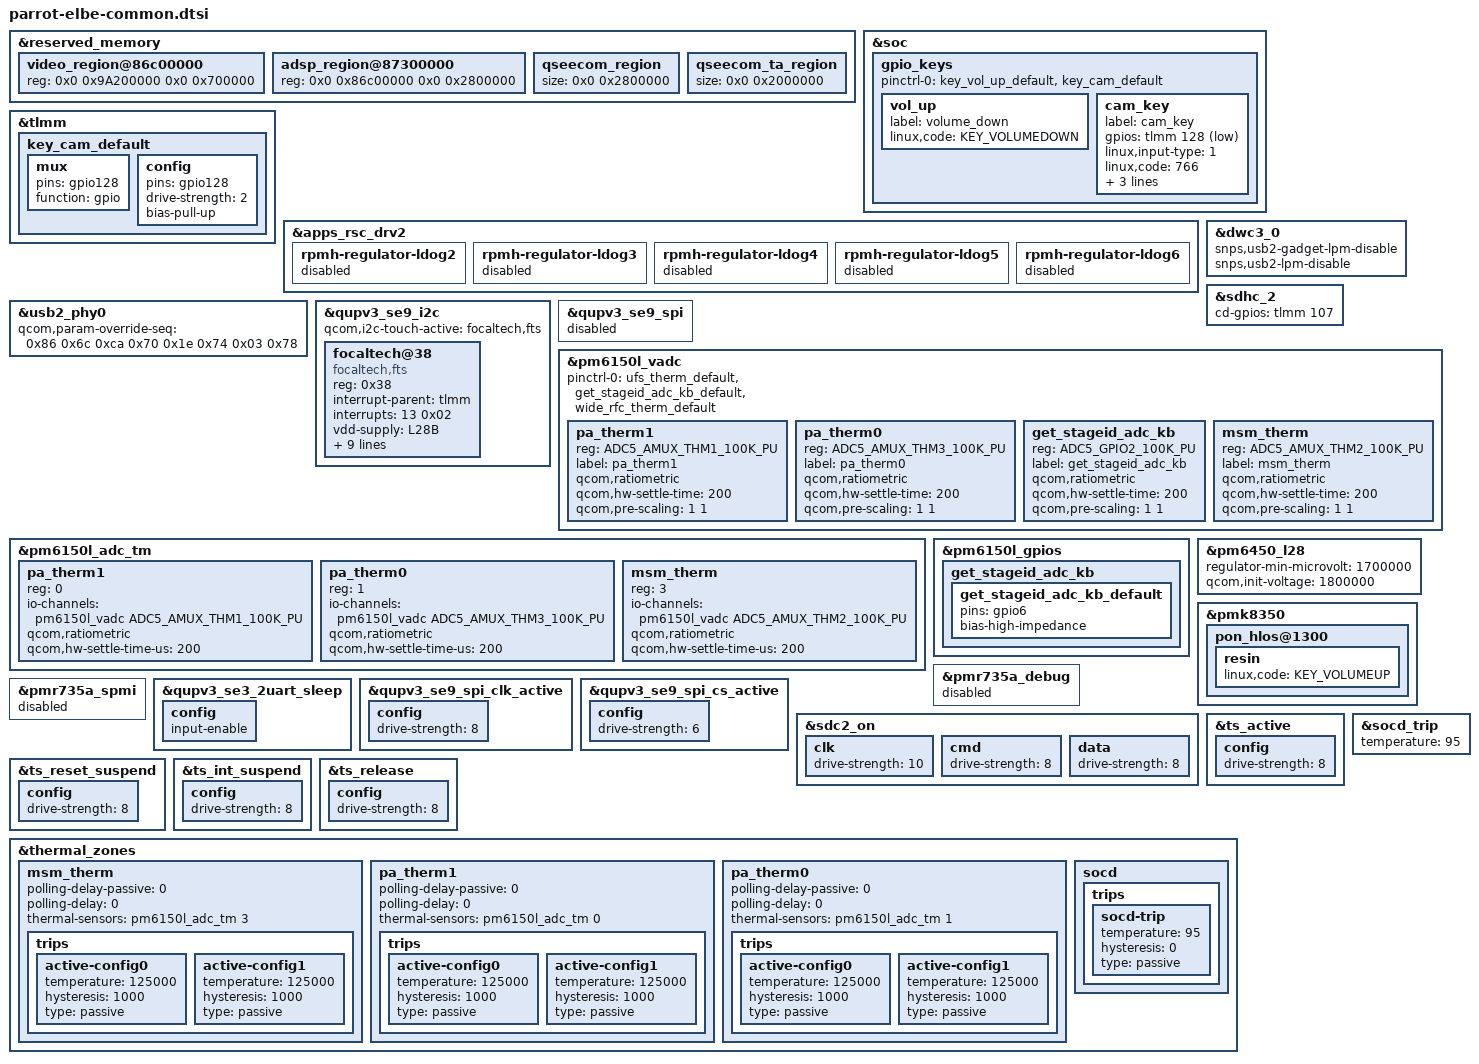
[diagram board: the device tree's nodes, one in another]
&reserved_memory {
	#address-cells = <2>;
	#size-cells = <2>;

	video_region@86c00000 {
		reg = <0x0 0x9A200000 0x0 0x700000>;
	};

	adsp_region@87300000 {
		reg = <0x0 0x86c00000 0x0 0x2800000>;
	};

	qseecom_region {
		size = <0x0 0x2800000>;
	};

	qseecom_ta_region {
		size = <0x0 0x2000000>;
	};
};

&soc {
	gpio_keys {
		pinctrl-0 = <&key_vol_up_default &key_cam_default>;

		vol_up {
			label = "volume_down";
			linux,code = <KEY_VOLUMEDOWN>;
		};

		cam_key {
			label = "cam_key";
			gpios = <&tlmm 128 GPIO_ACTIVE_LOW>;
			linux,input-type = <1>;
			linux,code = <766>;
			gpio-key,wakeup;
			debounce-interval = <15>;
			linux,can-disable;
		};
	};
};

&tlmm {
	key_cam_default: key_cam_default {
		mux {
			pins = "gpio128";
			function = "gpio";
		};

		config {
			pins = "gpio128";
			drive-strength = <2>;
			bias-pull-up;
		};
	};
};

&apps_rsc_drv2 {
	rpmh-regulator-ldog2 {
		status = "disabled";
	};

	rpmh-regulator-ldog3 {
		status = "disabled";
	};

	rpmh-regulator-ldog4 {
		status = "disabled";
	};

	rpmh-regulator-ldog5 {
		status = "disabled";
	};

	rpmh-regulator-ldog6 {
		status = "disabled";
	};
};

&dwc3_0 {
	snps,usb2-gadget-lpm-disable;
	snps,usb2-lpm-disable;
};

&usb2_phy0 {
	qcom,param-override-seq = <
		0x86 0x6c
		0xca 0x70
		0x1e 0x74
		0x03 0x78>;
};

&sdhc_2 {
	cd-gpios = <&tlmm 107 GPIO_ACTIVE_HIGH>;

	/delete-property/ no-sdio;
	/delete-property/ no-mmc;
};

&qupv3_se9_i2c {
	#address-cells = <1>;
	#size-cells = <0>;
	qcom,i2c-touch-active = "focaltech,fts";
	status = "okay";

	focaltech@38 {
		compatible = "focaltech,fts";
		reg = <0x38>;
		interrupt-parent = <&tlmm>;
		interrupts = <13 0x02>;
		vdd-supply = <&L28B>;
		focaltech,reset-gpio = <&tlmm 12 0x01>;
		focaltech,irq-gpio = <&tlmm 13 0x02>;
		focaltech,max-touch-number = <10>;
		focaltech,display-coords =  <0 0 1080 2340>;
		focaltech,avdd-gpio = <&tlmm 103 0x0>;
		pinctrl-names = "pmx_ts_active", "pmx_ts_suspend", "pmx_ts_release";
		pinctrl-0 = <&ts_active>;
		pinctrl-1 = <&ts_int_suspend &ts_reset_suspend>;
		pinctrl-2 = <&ts_release>;

		panel = <&dsi_samsung_amoled_cmd>;
	};
};

&qupv3_se9_spi {
	status = "disabled";
};

&pm6150l_vadc {
	pinctrl-0 = <&ufs_therm_default &get_stageid_adc_kb_default &wide_rfc_therm_default>;

	/delete-node/ pa_therm2;
	/delete-node/ pa_therm1;
	/delete-node/ wide_rfc_therm;

	pa_therm1 {
		reg = <ADC5_AMUX_THM1_100K_PU>;
		label = "pa_therm1";
		qcom,ratiometric;
		qcom,hw-settle-time = <200>;
		qcom,pre-scaling = <1 1>;
	};

	pa_therm0 {
		reg = <ADC5_AMUX_THM3_100K_PU>;
		label = "pa_therm0";
		qcom,ratiometric;
		qcom,hw-settle-time = <200>;
		qcom,pre-scaling = <1 1>;
	};

	get_stageid_adc_kb {
		reg = <ADC5_GPIO2_100K_PU>;
		label = "get_stageid_adc_kb";
		qcom,ratiometric;
		qcom,hw-settle-time = <200>;
		qcom,pre-scaling = <1 1>;
	};

	msm_therm {
		reg = <ADC5_AMUX_THM2_100K_PU>;
		label = "msm_therm";
		qcom,ratiometric;
		qcom,hw-settle-time = <200>;
		qcom,pre-scaling = <1 1>;
	};
};

&pm6150l_adc_tm {
	/delete-node/ pa_therm2;
	/delete-node/ pa_therm1;
	/delete-node/ wide_rfc_therm;

	pa_therm1 {
		reg = <0>;
		io-channels = <&pm6150l_vadc ADC5_AMUX_THM1_100K_PU>;
		qcom,ratiometric;
		qcom,hw-settle-time-us = <200>;
	};

	pa_therm0 {
		reg = <1>;
		io-channels = <&pm6150l_vadc ADC5_AMUX_THM3_100K_PU>;
		qcom,ratiometric;
		qcom,hw-settle-time-us = <200>;
	};

	msm_therm {
		reg = <3>;
		io-channels = <&pm6150l_vadc ADC5_AMUX_THM2_100K_PU>;
		qcom,ratiometric;
		qcom,hw-settle-time-us = <200>;
	};
};

&pm6150l_gpios {
	get_stageid_adc_kb {
		get_stageid_adc_kb_default: get_stageid_adc_kb_default {
			pins = "gpio6";
			bias-high-impedance;
		};
	};
};

&pm6450_l28 {
	regulator-min-microvolt = <1700000>;
	qcom,init-voltage = <1800000>;
};

&pmk8350 {
	pon_hlos@1300 {
		resin {
			linux,code = <KEY_VOLUMEUP>;
		};
	};
};

&pmr735a_debug {
	status = "disabled";
};

&pmr735a_spmi {
	status = "disabled";
};

&qupv3_se3_2uart_sleep {
	config {
		input-enable;
	};
};

&qupv3_se9_spi_clk_active {
	config {
		drive-strength = <8>;
	};
};

&qupv3_se9_spi_cs_active {
	config {
		drive-strength = <6>;
	};
};

&sdc2_on {
	clk {
		drive-strength = <10>;
	};

	cmd {
		drive-strength = <8>;
	};

	data {
		drive-strength = <8>;
	};
};

&ts_active {
	config {
		drive-strength = <8>;
	};
};

&ts_reset_suspend {
	config {
		drive-strength = <8>;
	};
};

&ts_int_suspend {
	config {
		drive-strength = <8>;
	};
};

&ts_release {
	config {
		drive-strength = <8>;
	};
};

&thermal_zones {
	/delete-node/ sys-therm-2;
	/delete-node/ sys-therm-4;
	/delete-node/ sys-therm-5;

	msm_therm {
		polling-delay-passive = <0>;
		polling-delay = <0>;
		thermal-sensors = <&pm6150l_adc_tm 3>;
		trips {
			active-config0 {
				temperature = <125000>;
				hysteresis = <1000>;
				type = "passive";
			};

			active-config1 {
				temperature = <125000>;
				hysteresis = <1000>;
				type = "passive";
			};
		};
	};

	pa_therm1 {
		polling-delay-passive = <0>;
		polling-delay = <0>;
		thermal-sensors = <&pm6150l_adc_tm 0>;
		trips {
			active-config0 {
				temperature = <125000>;
				hysteresis = <1000>;
				type = "passive";
			};

			active-config1 {
				temperature = <125000>;
				hysteresis = <1000>;
				type = "passive";
			};
		};
	};

	pa_therm0 {
		polling-delay-passive = <0>;
		polling-delay = <0>;
		thermal-sensors = <&pm6150l_adc_tm 1>;
		trips {
			active-config0 {
				temperature = <125000>;
				hysteresis = <1000>;
				type = "passive";
			};

			active-config1 {
				temperature = <125000>;
				hysteresis = <1000>;
				type = "passive";
			};
		};
	};

	socd {
		trips {
			socd-trip {
				temperature = <95>;
				hysteresis = <0>;
				type = "passive";
			};
		};
	};
};

&socd_trip {
	temperature = <95>;
};
